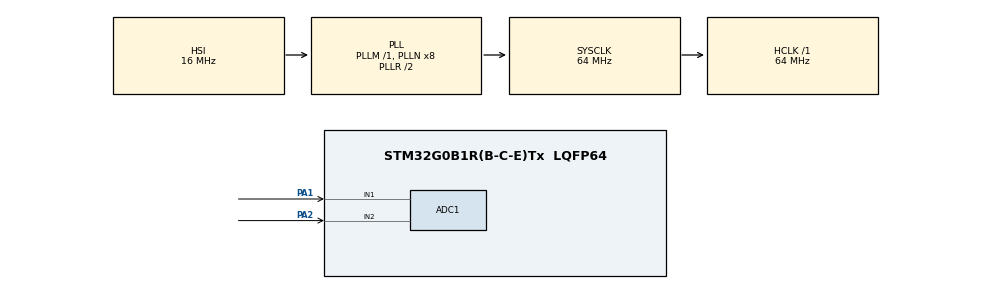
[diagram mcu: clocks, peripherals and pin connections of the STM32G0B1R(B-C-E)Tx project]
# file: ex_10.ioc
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ADC1.Channel-0\#ChannelRegularConversion=ADC_CHANNEL_1
ADC1.Channel-1\#ChannelRegularConversion=ADC_CHANNEL_2
ADC1.ContinuousConvMode=ENABLE
ADC1.NbrOfConversion=2
ADC1.NbrOfConversionFlag=1
ADC1.Rank-0\#ChannelRegularConversion=1
ADC1.Rank-1\#ChannelRegularConversion=2
ADC1.SamplingTime-0\#ChannelRegularConversion=ADC_SAMPLINGTIME_COMMON_1
ADC1.SamplingTime-1\#ChannelRegularConversion=ADC_SAMPLINGTIME_COMMON_1
ADC1.SamplingTimeCommon1=ADC_SAMPLETIME_160CYCLES_5
ADC1.SamplingTimeCommon2=ADC_SAMPLETIME_160CYCLES_5
ADC1.SelectedChannel=ADC_CHANNEL_1|ADC_CHANNEL_2
ADC1.master=1
Dma.ADC1.0.Direction=DMA_PERIPH_TO_MEMORY
Dma.ADC1.0.EventEnable=DISABLE
Dma.ADC1.0.Instance=DMA1_Channel1
Dma.ADC1.0.MemDataAlignment=DMA_MDATAALIGN_WORD
Dma.ADC1.0.MemInc=DMA_MINC_ENABLE
Dma.ADC1.0.Mode=DMA_CIRCULAR
Dma.ADC1.0.PeriphDataAlignment=DMA_PDATAALIGN_WORD
Dma.ADC1.0.PeriphInc=DMA_PINC_DISABLE
Dma.ADC1.0.Polarity=HAL_DMAMUX_REQ_GEN_RISING
Dma.ADC1.0.Priority=DMA_PRIORITY_LOW
Dma.ADC1.0.RequestNumber=1
Dma.ADC1.0.SignalID=NONE
Dma.ADC1.0.SyncEnable=DISABLE
Dma.ADC1.0.SyncPolarity=HAL_DMAMUX_SYNC_NO_EVENT
Dma.ADC1.0.SyncRequestNumber=1
Dma.ADC1.0.SyncSignalID=NONE
Dma.Request0=ADC1
Mcu.Family=STM32G0
Mcu.Name=STM32G0B1R(B-C-E)Tx
Mcu.Package=LQFP64
NVIC.DMA1_Channel1_IRQn=true\:0\:0\:false\:false\:true\:false\:true
PA1.Mode=IN1
PA1.Signal=ADC1_IN1
PA13.Mode=Serial_Wire
PA13.Signal=SYS_SWDIO
PA14-BOOT0.Mode=Serial_Wire
PA14-BOOT0.Signal=SYS_SWCLK
PA2.Mode=IN2
PA2.Signal=ADC1_IN2
PF0-OSC_IN\ (PF0).Mode=HSE-External-Oscillator
PF0-OSC_IN\ (PF0).Signal=RCC_OSC_IN
PF1-OSC_OUT\ (PF1).Mode=HSE-External-Oscillator
PF1-OSC_OUT\ (PF1).Signal=RCC_OSC_OUT
ProjectManager.HeapSize=0x200
ProjectManager.StackSize=0x400
ProjectManager.TargetToolchain=STM32CubeIDE
RCC.ADCFreq_Value=64000000
RCC.AHBFreq_Value=64000000
RCC.CortexFreq_Value=64000000
RCC.EXTERNAL_CLOCK_VALUE=48000
RCC.HCLKFreq_Value=64000000
RCC.HSE_VALUE=8000000
RCC.HSI48_VALUE=48000000
RCC.HSI_VALUE=16000000
RCC.LSE_VALUE=32768
RCC.SYSCLKFreq_VALUE=64000000
RCC.SYSCLKSource=RCC_SYSCLKSOURCE_PLLCLK
RCC.USBFreq_Value=48000000
RCC.VCOOutputFreq_Value=128000000
VP_SYS_VS_DBSignals.Mode=DisableDeadBatterySignals
board=custom

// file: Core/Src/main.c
/* USER CODE BEGIN Header */
/**
  ******************************************************************************
  * @file           : main.c
  * @brief          : Main program body
  ******************************************************************************
  * @attention
  *
  * Copyright (c) 2022 STMicroelectronics.
  * All rights reserved.
  *
  * This software is licensed under terms that can be found in the LICENSE file
  * in the root directory of this software component.
  * If no LICENSE file comes with this software, it is provided AS-IS.
  *
  ******************************************************************************
  */
/* USER CODE END Header */
#include "main.h"

ADC_HandleTypeDef hadc1;
DMA_HandleTypeDef hdma_adc1;

void SystemClock_Config(void);
static void MX_GPIO_Init(void);
static void MX_DMA_Init(void);
static void MX_ADC1_Init(void);

/* USER CODE BEGIN 0 */
	uint32_t VR[2], tmp[2];
	float Joy[2];
	uint8_t up = 0, down = 0, left = 0, right = 0, var = 0;
/* USER CODE END 0 */

int main(void)
{

  /* MCU Configuration--------------------------------------------------------*/

  /* Reset of all peripherals, Initializes the Flash interface and the Systick. */
  HAL_Init();

  /* Configure the system clock */
  SystemClock_Config();

  /* Initialize all configured peripherals */
  MX_GPIO_Init();
  MX_DMA_Init();
  MX_ADC1_Init();

  /* Infinite loop */
  /* USER CODE BEGIN WHILE */
  while (1)
  {
	  for (var = 0; var < 250; ++var) {
		 tmp[0] = tmp[0] + VR[0];
		 tmp[1] = tmp[1] + VR[1];
	  }

	  tmp[0] = tmp[0]/250;
	  tmp[1] = tmp[1]/250;

	  Joy[0] = (VR[0] / 20.475) - 100;
	  Joy[1] = (VR[1] / 20.475) - 100;

	  if(VR[1] < 2300 && VR[1] > 1900){
		 Joy[1] = 0;
	  }
	  if(VR[0] < 2300 && VR[0] > 1900){
	  	  Joy[0] = 0;
	  }

	   if(Joy[0] > 70){
		   left = 1;
	   }else left = 0;

	   if(Joy[0] < 0){
	   		   right = 1;
	   }else right = 0;

	   if(Joy[1] > 70){
	   		   up = 1;
	   }else up = 0;

	   if(Joy[1] < 0){
	   		   down = 1;
	   }else down = 0;

    /* USER CODE END WHILE */

    /* USER CODE BEGIN 3 */
	  HAL_ADC_Start_DMA(&hadc1, VR, 2);
  }
  /* USER CODE END 3 */
}

void SystemClock_Config(void)
{
  RCC_OscInitTypeDef RCC_OscInitStruct = {0};
  RCC_ClkInitTypeDef RCC_ClkInitStruct = {0};

  /** Configure the main internal regulator output voltage
  */
  HAL_PWREx_ControlVoltageScaling(PWR_REGULATOR_VOLTAGE_SCALE1);
  /** Initializes the RCC Oscillators according to the specified parameters
  * in the RCC_OscInitTypeDef structure.
  */
  RCC_OscInitStruct.OscillatorType = RCC_OSCILLATORTYPE_HSI;
  RCC_OscInitStruct.HSIState = RCC_HSI_ON;
  RCC_OscInitStruct.HSIDiv = RCC_HSI_DIV1;
  RCC_OscInitStruct.HSICalibrationValue = RCC_HSICALIBRATION_DEFAULT;
  RCC_OscInitStruct.PLL.PLLState = RCC_PLL_ON;
  RCC_OscInitStruct.PLL.PLLSource = RCC_PLLSOURCE_HSI;
  RCC_OscInitStruct.PLL.PLLM = RCC_PLLM_DIV1;
  RCC_OscInitStruct.PLL.PLLN = 8;
  RCC_OscInitStruct.PLL.PLLP = RCC_PLLP_DIV2;
  RCC_OscInitStruct.PLL.PLLQ = RCC_PLLQ_DIV2;
  RCC_OscInitStruct.PLL.PLLR = RCC_PLLR_DIV2;
  if (HAL_RCC_OscConfig(&RCC_OscInitStruct) != HAL_OK)
  {
    Error_Handler();
  }
  /** Initializes the CPU, AHB and APB buses clocks
  */
  RCC_ClkInitStruct.ClockType = RCC_CLOCKTYPE_HCLK|RCC_CLOCKTYPE_SYSCLK
                              |RCC_CLOCKTYPE_PCLK1;
  RCC_ClkInitStruct.SYSCLKSource = RCC_SYSCLKSOURCE_PLLCLK;
  RCC_ClkInitStruct.AHBCLKDivider = RCC_SYSCLK_DIV1;
  RCC_ClkInitStruct.APB1CLKDivider = RCC_HCLK_DIV1;

  if (HAL_RCC_ClockConfig(&RCC_ClkInitStruct, FLASH_LATENCY_2) != HAL_OK)
  {
    Error_Handler();
  }
}

static void MX_ADC1_Init(void)
{

  ADC_ChannelConfTypeDef sConfig = {0};

  /** Configure the global features of the ADC (Clock, Resolution, Data Alignment and number of conversion)
  */
  hadc1.Instance = ADC1;
  hadc1.Init.ClockPrescaler = ADC_CLOCK_SYNC_PCLK_DIV2;
  hadc1.Init.Resolution = ADC_RESOLUTION_12B;
  hadc1.Init.DataAlign = ADC_DATAALIGN_RIGHT;
  hadc1.Init.ScanConvMode = ADC_SCAN_ENABLE;
  hadc1.Init.EOCSelection = ADC_EOC_SINGLE_CONV;
  hadc1.Init.LowPowerAutoWait = DISABLE;
  hadc1.Init.LowPowerAutoPowerOff = DISABLE;
  hadc1.Init.ContinuousConvMode = ENABLE;
  hadc1.Init.NbrOfConversion = 2;
  hadc1.Init.DiscontinuousConvMode = DISABLE;
  hadc1.Init.ExternalTrigConv = ADC_SOFTWARE_START;
  hadc1.Init.ExternalTrigConvEdge = ADC_EXTERNALTRIGCONVEDGE_NONE;
  hadc1.Init.DMAContinuousRequests = DISABLE;
  hadc1.Init.Overrun = ADC_OVR_DATA_PRESERVED;
  hadc1.Init.SamplingTimeCommon1 = ADC_SAMPLETIME_160CYCLES_5;
  hadc1.Init.SamplingTimeCommon2 = ADC_SAMPLETIME_160CYCLES_5;
  hadc1.Init.OversamplingMode = DISABLE;
  hadc1.Init.TriggerFrequencyMode = ADC_TRIGGER_FREQ_HIGH;
  if (HAL_ADC_Init(&hadc1) != HAL_OK)
  {
    Error_Handler();
  }
  /** Configure Regular Channel
  */
  sConfig.Channel = ADC_CHANNEL_1;
  sConfig.Rank = ADC_REGULAR_RANK_1;
  sConfig.SamplingTime = ADC_SAMPLINGTIME_COMMON_1;
  if (HAL_ADC_ConfigChannel(&hadc1, &sConfig) != HAL_OK)
  {
    Error_Handler();
  }
  /** Configure Regular Channel
  */
  sConfig.Channel = ADC_CHANNEL_2;
  sConfig.Rank = ADC_REGULAR_RANK_2;
  if (HAL_ADC_ConfigChannel(&hadc1, &sConfig) != HAL_OK)
  {
    Error_Handler();
  }

}

static void MX_DMA_Init(void)
{

  /* DMA controller clock enable */
  __HAL_RCC_DMA1_CLK_ENABLE();

  /* DMA interrupt init */
  /* DMA1_Channel1_IRQn interrupt configuration */
  HAL_NVIC_SetPriority(DMA1_Channel1_IRQn, 0, 0);
  HAL_NVIC_EnableIRQ(DMA1_Channel1_IRQn);

}

static void MX_GPIO_Init(void)
{

  /* GPIO Ports Clock Enable */
  __HAL_RCC_GPIOF_CLK_ENABLE();
  __HAL_RCC_GPIOA_CLK_ENABLE();

}

void Error_Handler(void)
{
  __disable_irq();
  while (1)
  {
  }
}
